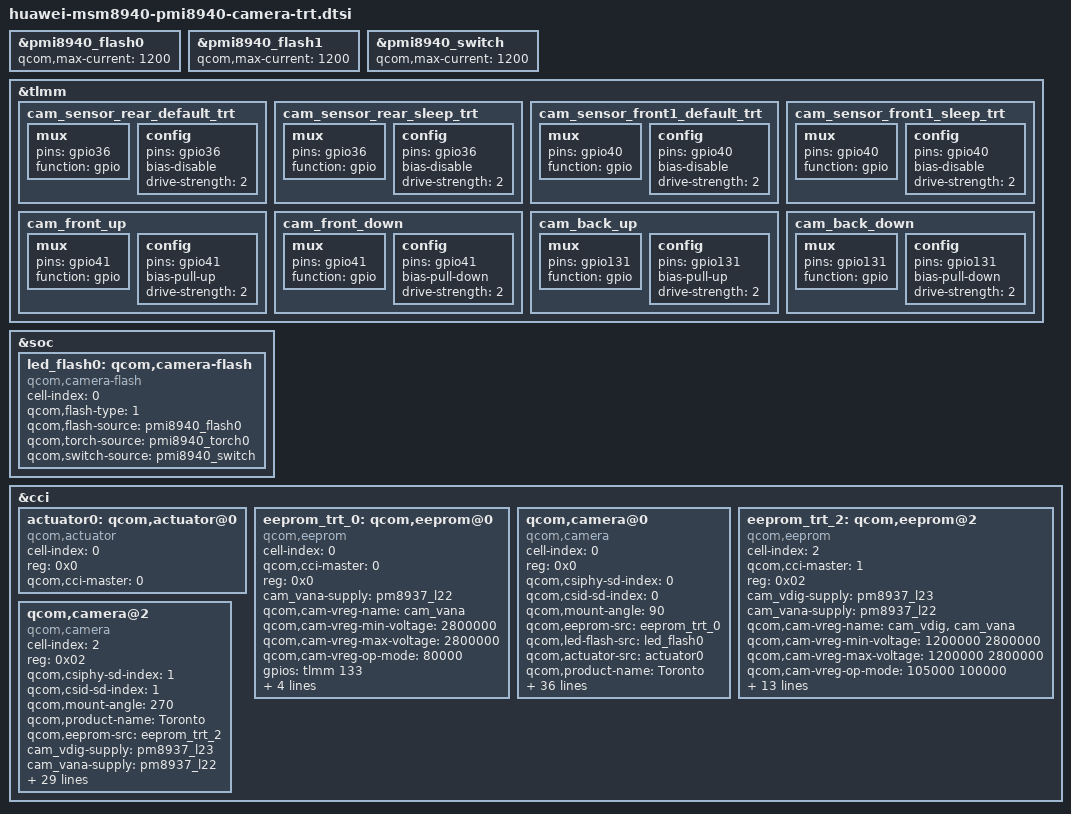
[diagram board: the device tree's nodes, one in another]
/*
 * Copyright (c) 2015-2016, The Linux Foundation. All rights reserved.
 *
 * This program is free software; you can redistribute it and/or modify
 * it under the terms of the GNU General Public License version 2 and
 * only version 2 as published by the Free Software Foundation.
 *
 * This program is distributed in the hope that it will be useful,
 * but WITHOUT ANY WARRANTY; without even the implied warranty of
 * MERCHANTABILITY or FITNESS FOR A PARTICULAR PURPOSE.  See the
 * GNU General Public License for more details.
 */
&pmi8940_flash0 {
	qcom,max-current = <1200>;
};
&pmi8940_flash1 {
	qcom,max-current = <1200>;
};
&pmi8940_switch {
	qcom,max-current = <1200>;
};
&tlmm {
	cam_sensor_rear_default_trt: cam_sensor_rear_default_trt {
		/* reset*/
		mux {
			pins = "gpio36";
			function = "gpio";
		};

		config {
			pins = "gpio36";
			bias-disable; /* No PULL */
			drive-strength = <2>; /* 2 MA */
		};
	};
	cam_sensor_rear_sleep_trt: cam_sensor_rear_sleep_trt {
		/* reset*/
		mux {
			pins = "gpio36";
			function = "gpio";
		};

		config {
			pins = "gpio36";
			bias-disable; /* No PULL */
			drive-strength = <2>; /* 2 MA */
		};
	};
	cam_sensor_front1_default_trt: cam_sensor_front1_default_trt {
		/* reset*/
		mux {
			pins = "gpio40";
			function = "gpio";
		};

		config {
			pins = "gpio40";
			bias-disable; /* No PULL */
			drive-strength = <2>; /* 2 MA */
		};
	};
	cam_sensor_front1_sleep_trt: cam_sensor_front1_sleep_trt {
		/* reset*/
		mux {
			pins = "gpio40";
			function = "gpio";
		};

		config {
			pins = "gpio40";
			bias-disable; /* No PULL */
			drive-strength = <2>; /* 2 MA */
		};
	};
	cam_front_up: cam_front_up {
		/* reset*/
		mux {
			pins = "gpio41";
			function = "gpio";
		};

		config {
			pins = "gpio41";
			bias-pull-up; /* PULL UP*/
			drive-strength = <2>; /* 2 MA */
		};
	};
	cam_front_down: cam_front_down {
		/* reset*/
		mux {
			pins = "gpio41";
			function = "gpio";
		};

		config {
			pins = "gpio41";
			bias-pull-down; /* No PULL */
			drive-strength = <2>; /* 2 MA */
		};
	};

        cam_back_up: cam_back_up {
                /* reset*/
                mux {
                        pins = "gpio131";
                        function = "gpio";
                };

                config {
                        pins = "gpio131";
                        bias-pull-up; /* PULL UP*/
                        drive-strength = <2>; /* 2 MA */
                };
        };
        cam_back_down: cam_back_down {
                /* reset*/
                mux {
                        pins = "gpio131";
                        function = "gpio";
                };

                config {
                        pins = "gpio131";
                        bias-pull-down; /* No PULL */
                        drive-strength = <2>; /* 2 MA */
                };
        };
};
&soc {
        led_flash0: qcom,camera-flash {
                cell-index = <0>;
                compatible = "qcom,camera-flash";
                qcom,flash-type = <1>;
                qcom,flash-source = <&pmi8940_flash0>;
                qcom,torch-source = <&pmi8940_torch0>;
                qcom,switch-source = <&pmi8940_switch>;
        };
};

&cci {
	actuator0: qcom,actuator@0 {
		cell-index = <0>;
		reg = <0x0>;
		compatible = "qcom,actuator";
		qcom,cci-master = <0>;
	};

	eeprom_trt_0: qcom,eeprom@0 {
		cell-index = <0>;
		compatible = "qcom,eeprom";
		qcom,cci-master = <0>;
		reg = <0x0>;
		cam_vana-supply = <&pm8937_l22>;
		qcom,cam-vreg-name = "cam_vana";
		qcom,cam-vreg-min-voltage = <2800000>;
		qcom,cam-vreg-max-voltage = <2800000>;
		qcom,cam-vreg-op-mode = <80000>;
		gpios = <&tlmm 133 0>;
		qcom,gpio-vio = <0>;
		qcom,gpio-req-tbl-num = <0>;
		qcom,gpio-req-tbl-flags = <0>;
		qcom,gpio-req-tbl-label = "CAM_VIO0";
		status = "ok";
	};

	qcom,camera@0 {
		cell-index = <0>;
		compatible = "qcom,camera";
		reg = <0x0>;
		qcom,csiphy-sd-index = <0>;
		qcom,csid-sd-index = <0>;
		qcom,mount-angle = <90>;
		qcom,eeprom-src = <&eeprom_trt_0>;
		qcom,led-flash-src = <&led_flash0>;
		qcom,actuator-src = <&actuator0>;
		qcom,product-name = "Toronto";
		cam_vdig-supply = <&pm8937_l23>;
		cam_vana-supply = <&pm8937_l22>;
		cam_vaf-supply = <&pm8937_l17>;
		qcom,cam-vreg-name = "cam_vdig", "cam_vana", "cam_vaf";
		qcom,cam-vreg-min-voltage = <1200000 2800000 2850000>;
		qcom,cam-vreg-max-voltage = <1200000 2800000 2850000>;
		qcom,cam-vreg-op-mode = <105000 80000 100000>;
		pinctrl-names = "cam_default", "cam_suspend", "cam_up", "cam_down";
		pinctrl-0 = <&cam_sensor_mclk0_default &cam_sensor_rear_default_trt &cam_back_up>;
		pinctrl-1 = <&cam_sensor_mclk0_sleep &cam_sensor_rear_sleep_trt &cam_back_up>;
		pinctrl-2 = <&cam_sensor_mclk0_default &cam_sensor_rear_default_trt &cam_back_up>;
		pinctrl-3 = <&cam_sensor_mclk0_default &cam_sensor_rear_default_trt &cam_back_down>;
		gpios = <&tlmm 26 0>,
			<&tlmm 36 0>,
			<&tlmm 35 0>,
			<&tlmm 133 0>,
			<&tlmm 131 0>,
			<&tlmm 132 0>;
		qcom,gpio-reset = <1>;
		qcom,gpio-af-pwdm = <2>;
		qcom,gpio-vio = <3>;
		qcom,gpio-cam-id = <4>;
		qcom,gpio-vdig = <5>;/*front camera vdig*/
		qcom,gpio-req-tbl-num = <0 1 2 3 4 5>;
		qcom,gpio-req-tbl-flags = <1 0 0 0 1 0>;
		qcom,gpio-req-tbl-label = "CAMIF_MCLK0",
			"CAM_RESET0",
			"CAM_AF_PWDM0",
			"CAM_VIO0",
			"CAM_ID0",
			"CAM_VDIG0";
		qcom,sensor-position = <0>;
		qcom,sensor-mode = <0>;
		qcom,cci-master = <0>;
		status = "ok";
		clocks = <&clock_gcc clk_mclk0_clk_src>,
				<&clock_gcc clk_gcc_camss_mclk0_clk>;
		clock-names = "cam_src_clk", "cam_clk";
		qcom,clock-rates = <24000000 0>;
	};
	eeprom_trt_2: qcom,eeprom@2 {
		cell-index = <2>;
		compatible = "qcom,eeprom";
		qcom,cci-master = <1>;
		reg = <0x02>;
		cam_vdig-supply = <&pm8937_l23>;/*back camera vdig*/
		cam_vana-supply = <&pm8937_l22>;
		qcom,cam-vreg-name ="cam_vdig", "cam_vana";
		qcom,cam-vreg-min-voltage = <1200000 2800000>;
		qcom,cam-vreg-max-voltage = <1200000 2800000>;
		qcom,cam-vreg-op-mode = <105000 100000>;
		gpios = <&tlmm 28 0>,
			<&tlmm 40 0>,
			<&tlmm 132 0>,
			<&tlmm 133 0>,
			<&tlmm 41 0>;
		qcom,gpio-reset = <1>;
		qcom,gpio-vdig = <2>;
		qcom,gpio-vio = <3>;
		qcom,gpio-cam-id = <4>;
		qcom,gpio-req-tbl-num = <0 1 2 3 4>;
		qcom,gpio-req-tbl-flags = <1 0 0 0 1>;
		qcom,gpio-req-tbl-label = "CAMIF_MCLK2",
					  "CAM_RESET2",
					  "CAM_VDIG2",
					  "CAM_VIO2",
					  "CAM_ID2";
		status = "ok";
		clocks = <&clock_gcc clk_mclk2_clk_src>,
			<&clock_gcc clk_gcc_camss_mclk2_clk>;
		clock-names = "cam_src_clk", "cam_clk";
		qcom,clock-rates = <24000000 0>;
	};
	qcom,camera@2 {
		cell-index = <2>;
		compatible = "qcom,camera";
		reg = <0x02>;
		qcom,csiphy-sd-index = <1>;
		qcom,csid-sd-index = <1>;
		qcom,mount-angle = <270>;
		qcom,product-name = "Toronto";
		qcom,eeprom-src = <&eeprom_trt_2>;
		cam_vdig-supply = <&pm8937_l23>;/*back camera vdig*/
		cam_vana-supply = <&pm8937_l22>;
		qcom,cam-vreg-name ="cam_vdig", "cam_vana";
		qcom,cam-vreg-min-voltage = <1200000 2800000>;
		qcom,cam-vreg-max-voltage = <1200000 2800000>;
		qcom,cam-vreg-op-mode = <105000 100000>;
		pinctrl-names = "cam_default", "cam_suspend", "cam_up","cam_down";
		pinctrl-0 = <&cam_sensor_mclk2_default &cam_sensor_front1_default_trt &cam_front_up>;
		pinctrl-1 = <&cam_sensor_mclk2_sleep &cam_sensor_front1_sleep_trt &cam_front_up>;
		pinctrl-2 = <&cam_sensor_mclk2_default &cam_sensor_front1_default_trt &cam_front_up>;
		pinctrl-3 = <&cam_sensor_mclk2_default &cam_sensor_front1_default_trt &cam_front_down>;
		gpios = <&tlmm 28 0>,
			<&tlmm 40 0>,
			<&tlmm 132 0>,
			<&tlmm 133 0>,
			<&tlmm 41 0>;
		qcom,gpio-reset = <1>;
		qcom,gpio-vdig = <2>;
		qcom,gpio-vio = <3>;
		qcom,gpio-cam-id = <4>;
		qcom,gpio-req-tbl-num = <0 1 2 3 4>;
		qcom,gpio-req-tbl-flags = <1 0 0 0 1>;
		qcom,gpio-req-tbl-label = "CAMIF_MCLK2",
					  "CAM_RESET2",
					  "CAM_VDIG2",
					  "CAM_VIO2",
					  "CAM_ID2";
		qcom,sensor-position = <1>;
		qcom,sensor-mode = <0>;
		qcom,cci-master = <1>;
		status = "ok";
		clocks = <&clock_gcc clk_mclk2_clk_src>,
			<&clock_gcc clk_gcc_camss_mclk2_clk>;
		clock-names = "cam_src_clk", "cam_clk";
		qcom,clock-rates = <24000000 0>;
	};
};
